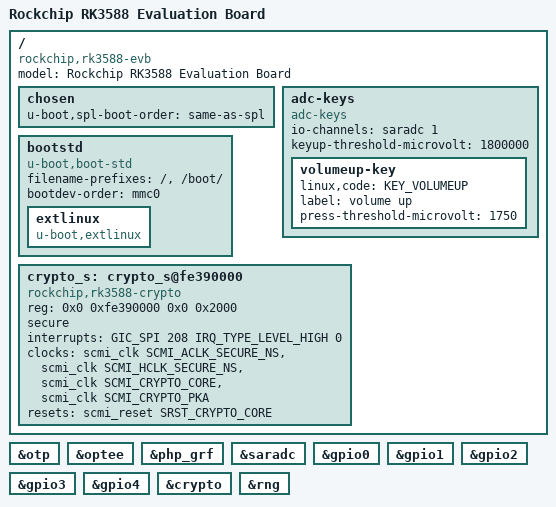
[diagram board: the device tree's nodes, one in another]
// SPDX-License-Identifier: (GPL-2.0+ OR MIT)
/*
 * Copyright (c) 2023 Rockchip Electronics Co., Ltd.
 */

#include "rk3588-u-boot.dtsi"
#include <dt-bindings/input/input.h>

/ {
	model = "Rockchip RK3588 Evaluation Board";
	compatible = "rockchip,rk3588-evb", "rockchip,rk3588";

	chosen {
		u-boot,spl-boot-order = &sdmmc, "same-as-spl", &sdhci;
	};

	adc-keys {
		compatible = "adc-keys";
		io-channels = <&saradc 1>;
		io-channel-names = "buttons";
		keyup-threshold-microvolt = <1800000>;
		bootph-all;
		status = "okay";

		volumeup-key {
			bootph-all;
			linux,code = <KEY_VOLUMEUP>;
			label = "volume up";
			press-threshold-microvolt = <1750>;
		};
	};

	bootstd {
		compatible = "u-boot,boot-std";
		bootph-all;
		filename-prefixes = "/", "/boot/";
		bootdev-order = "mmc0";

		extlinux {
			bootph-all;
			compatible = "u-boot,extlinux";
		};
	};

	crypto_s: crypto_s@fe390000 {
		compatible = "rockchip,rk3588-crypto";
		reg = <0x0 0xfe390000 0x0 0x2000>;
		secure;
		interrupts = <GIC_SPI 208 IRQ_TYPE_LEVEL_HIGH 0>;
		clocks = <&scmi_clk SCMI_ACLK_SECURE_NS>, <&scmi_clk SCMI_HCLK_SECURE_NS>,
			 <&scmi_clk SCMI_CRYPTO_CORE>, <&scmi_clk SCMI_CRYPTO_PKA>;
		clock-names = "aclk", "hclk", "sclk", "pka";
		resets = <&scmi_reset SRST_CRYPTO_CORE>;
		reset-names = "crypto-rst";
		status = "disabled";
	};
};

&otp {
	bootph-all;
	status = "okay";
};

&optee {
	bootph-all;
};

&php_grf {
	bootph-all;
};

&saradc {
	bootph-all;
	status = "okay";
};

&gpio0 {
	bootph-all;
	status = "okay";
};

&gpio1 {
	bootph-all;
	status = "okay";
};

&gpio2 {
	bootph-all;
	status = "okay";
};

&gpio3 {
	bootph-all;
	status = "okay";
};

&gpio4 {
	bootph-all;
	status = "okay";
};

&crypto {
	bootph-all;
	status = "okay";
};

&crypto_s {
	bootph-all;
	status = "okay";
};

&rng {
	bootph-all;
	status = "okay";
};


